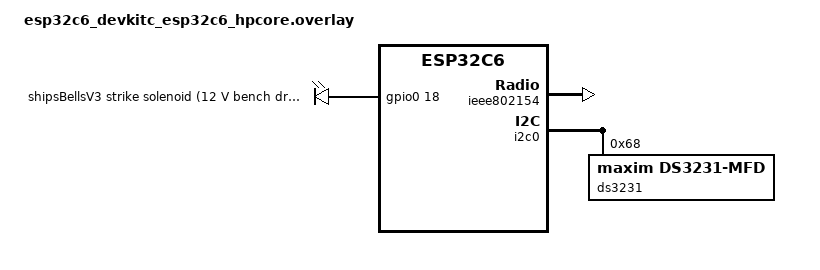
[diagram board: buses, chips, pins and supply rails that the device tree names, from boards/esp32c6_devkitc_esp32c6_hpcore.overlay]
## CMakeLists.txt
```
cmake_minimum_required(VERSION 3.20.0)
find_package(Zephyr REQUIRED HINTS $ENV{ZEPHYR_BASE})
project(tuvm_pulse)

# Task 7 (native_sim bring-up gate): the Model A ("solidified image") boot
# path — vm.c/gc.c/dispatch.c + a per-program src/solidified_image.c baked by
# tools/ns_compile_oevm.py from zephyr/PulseNode.nsl, exactly the recipe
# tools/run_tests_oevm.py uses for the host Path-A test runner (oevm_runner),
# minus src/oevm_main.c (this directory's src/main.c is the Zephyr entry
# point instead). Only src/kernel_boot.c is mutually exclusive with
# solidified_image.c: it defines 13 `Vtable_*` symbols (Vtable_SymbolVtable,
# Vtable_IntegerVtable, ...) that solidified_image.c also bakes for THIS program
# — verified, the overlap is exactly those 13. src/oimg_loader.c does NOT clash
# and is linked under BOTH models: it shares no symbol with solidified_image.c,
# and the host has always linked the two together — tools/run_c_tests.sh:28
# (ENG_A = oimg_loader.c + solidified_image.c) vs :29 (ENG_B = oimg_loader.c +
# kernel_boot.c). The TUVM_MODEL knob below is that same ENG_A/ENG_B split.
# (An earlier revision of this comment blamed oimg_loader.c too, and cited a
# run_c_unit_tests() in tools/run_tests_oevm.py that does not exist — the real
# link sets are in run_c_tests.sh.) src/serial.c and src/udp.c are linked even
# though this gate's node grants no serial/net capability: src/dispatch.c's
# send() fast path unconditionally calls serial_object()/udp_object() to test
# receiver identity, so both — and the zephyr backend files that back them —
# must link regardless (hence prj.conf's native_sim NSOS networking block).
set(TUVM_SRC ${CMAKE_CURRENT_SOURCE_DIR}/..)
target_sources(app PRIVATE
  src/main.c
  ${TUVM_SRC}/src/vm.c ${TUVM_SRC}/src/gc.c ${TUVM_SRC}/src/dispatch.c
  ${TUVM_SRC}/src/platform.c ${TUVM_SRC}/src/space.c ${TUVM_SRC}/src/handles.c
  ${TUVM_SRC}/src/span.c
  ${TUVM_SRC}/src/serial.c ${TUVM_SRC}/src/udp.c ${TUVM_SRC}/src/mirror.c
  ${TUVM_SRC}/src/backend/zephyr/platform_zephyr.c
  ${TUVM_SRC}/src/backend/zephyr/serial_zephyr.c
  ${TUVM_SRC}/src/backend/zephyr/udp_zephyr.c
  ${TUVM_SRC}/src/backend/zephyr/pulse_zephyr.c
  ${TUVM_SRC}/src/backend/zephyr/timer_zephyr.c
  ${TUVM_SRC}/src/backend/zephyr/span_zephyr.c
  ${TUVM_SRC}/src/backend/zephyr/sensor_zephyr.c
  ${TUVM_SRC}/src/http.c
  ${TUVM_SRC}/src/http_core.c
  ${TUVM_SRC}/src/backend/zephyr/http_zephyr.c
)
target_include_directories(app PRIVATE ${TUVM_SRC}/src)

# OpenThread bring-up TU (tuvm_thread_bringup). Gated on OPENTHREAD so the WROOM
# (WiFi, no Thread) compiles it away. ONE shared impl: nRF (NCS) and C6 (upstream
# 4.2) expose the same no-arg OT API, so the earlier board split was redundant
# (#59, 2026-07-20). Re-split behind thread_bringup.h only if the APIs diverge.
if (CONFIG_NET_L2_OPENTHREAD)
  target_sources(app PRIVATE src/thread_bringup.c)
endif()

# ---- Model A/B knob -------------------------------------------------------
# A (default): the per-program baked image, src/solidified_image.c.
# B: a generic VM + a .oimg blob .incbin'd into flash .rodata.
# The link sets are MUTUALLY EXCLUSIVE: solidified_image.c XOR kernel_boot.c —
# see the 13-symbol Vtable_* overlap explained at the top of this file. This is
# the ENG_A/ENG_B split tools/run_c_tests.sh has always used on the host.
#
# Model A links no oimg_loader.c: zephyr/src/main.c stubs the four globals it
# would own (oimg_blob_base/_end, builtin_registry, oimg_singleton), and
# oimg.h's is_in_blob() returns 0 while oimg_blob_base is NULL, so the XIP
# accessor paths are never taken.
set(TUVM_MODEL "B" CACHE STRING "tuvm image model: A (solidified) or B (.oimg blob)")
set_property(CACHE TUVM_MODEL PROPERTY STRINGS A B)

if(TUVM_MODEL STREQUAL "A")
  target_sources(app PRIVATE ${TUVM_SRC}/src/solidified_image.c)
elseif(TUVM_MODEL STREQUAL "B")
  if(NOT DEFINED TUVM_BLOB)
    # Model B is the device default; a bare `west build` (no run.sh, no
    # -DTUVM_BLOB) falls back to the committed TimerNode image so it just works.
    # run.sh bakes a fresh <node>.oimg and passes -DTUVM_BLOB, overriding this.
    set(TUVM_BLOB ${CMAKE_CURRENT_SOURCE_DIR}/TimerNode.oimg)
    message(STATUS "tuvm: TUVM_BLOB defaulted to ${TUVM_BLOB}")
  endif()
  if(NOT EXISTS "${TUVM_BLOB}")
    message(FATAL_ERROR "TUVM_BLOB does not exist: ${TUVM_BLOB}")
  endif()
  target_sources(app PRIVATE
    ${TUVM_SRC}/src/oimg_loader.c
    ${TUVM_SRC}/src/kernel_boot.c
    ${TUVM_SRC}/src/hanoi_native.c
    ${CMAKE_CURRENT_SOURCE_DIR}/blob.S)
  # OEVM_NO_FILE_IO compiles out oimg_loader.c's oimg_load() mmap/open path,
  # which has no meaning on this target.
  target_compile_definitions(app PRIVATE TUVM_MODEL_B OEVM_NO_FILE_IO)
  # blob.S is preprocessed (.S, capital) so TUVM_BLOB_FILE expands.
  set_property(SOURCE ${CMAKE_CURRENT_SOURCE_DIR}/blob.S APPEND PROPERTY
    COMPILE_DEFINITIONS "TUVM_BLOB_FILE=\"${TUVM_BLOB}\"")
  # Rebuild when the blob changes.
  set_property(SOURCE ${CMAKE_CURRENT_SOURCE_DIR}/blob.S APPEND PROPERTY
    OBJECT_DEPENDS "${TUVM_BLOB}")
else()
  message(FATAL_ERROR "TUVM_MODEL must be A or B, got: ${TUVM_MODEL}")
endif()
message(STATUS "tuvm: TUVM_MODEL=${TUVM_MODEL}")

# Tunables via ENV, not `-D`: NCS sysbuild swallows a bare
# `west build -- -DOEVM_HEAP_SIZE=...` (it lands in the sysbuild cache, never
# the app image) — same wrinkle ns-zephyr/app/CMakeLists.txt documents. Env
# vars are inherited by this CMake invocation unconditionally.
if(DEFINED ENV{OEVM_HEAP_SIZE})
  target_compile_definitions(app PRIVATE OEVM_HEAP_SIZE=$ENV{OEVM_HEAP_SIZE})
endif()

# The VM's method/prim inline caches (dispatch.c) default to 4096 entries each
# — 64 KB + 32 KB of static SRAM, host-generous. On the 256 KB nRF52840 that
# dwarfs the arena, so Task 8's DK build shrinks them via env (same env-not-`-D`
# reason as OEVM_HEAP_SIZE above: NCS sysbuild swallows bare `-D` app defines).
# They are pure caches — a smaller table only trades a few more collisions, never
# correctness.
if(DEFINED ENV{METHOD_CACHE_SIZE})
  target_compile_definitions(app PRIVATE METHOD_CACHE_SIZE=$ENV{METHOD_CACHE_SIZE})
endif()
if(DEFINED ENV{PRIM_CACHE_SIZE})
  target_compile_definitions(app PRIVATE PRIM_CACHE_SIZE=$ENV{PRIM_CACHE_SIZE})
endif()

# The boxed-Float arena (gc.c) mallocs slabs of OEVM_FLOAT_ARENA_SLAB_CELLS floats
# (default 4096 ≈ 64 KB/slab — sized for a host's big libc heap). On the DK the
# newlib k_malloc pool is a few tens of KB, so a float-heavy program (e.g.
# perfstex's floatMath) must shrink the slab and bound the slab count via env.
if(DEFINED ENV{OEVM_FLOAT_ARENA_SLAB_CELLS})
  target_compile_definitions(app PRIVATE OEVM_FLOAT_ARENA_SLAB_CELLS=$ENV{OEVM_FLOAT_ARENA_SLAB_CELLS})
endif()
if(DEFINED ENV{OEVM_FLOAT_ARENA_SLAB_BUDGET})
  target_compile_definitions(app PRIVATE OEVM_FLOAT_ARENA_SLAB_BUDGET=$ENV{OEVM_FLOAT_ARENA_SLAB_BUDGET})
endif()

# The VM execution stack (vm.c) is a fixed heap Stack object of VM_STACK_INIT_WORDS
# oops, allocated at boot INSIDE the OEVM_HEAP_SIZE arena — the single largest boot
# allocation (default 16384 words = 64 KB on the 32-bit DK). Shrinking it lowers the
# arena floor, so OEVM_HEAP_SIZE can drop too. OEVM_MARK_STACK_SIZE (gc.c) is the GC
# mark worklist. Both are embedded RAM knobs; passed via env for the same NCS-sysbuild
# reason as the arena/cache defines above.
if(DEFINED ENV{VM_STACK_INIT_WORDS})
  target_compile_definitions(app PRIVATE VM_STACK_INIT_WORDS=$ENV{VM_STACK_INIT_WORDS})
endif()
if(DEFINED ENV{OEVM_MARK_STACK_SIZE})
  target_compile_definitions(app PRIVATE OEVM_MARK_STACK_SIZE=$ENV{OEVM_MARK_STACK_SIZE})
endif()

# Hot-path IRAM placement. Routes the interpreter's hottest functions
# (oevm.h OEVM_HOT) into internal IRAM instead of flash XIP; ends the
# combinator-row cache roulette (ledger E8: ocDo −36%, ~8 KB IRAM).
# Xtensa-only: -mtext-section-literals keeps literal pools in the relocated
# section (an L32R in IRAM cannot reach flash). DEFAULT ON for Xtensa
# (accepted 2026-07-17); export OEVM_IRAM_HOT=0 to opt out. Env, not -D,
# for the same NCS-sysbuild reason as the defines above.
if(CONFIG_XTENSA AND NOT "$ENV{OEVM_IRAM_HOT}" STREQUAL "0")
  target_compile_definitions(app PRIVATE OEVM_HOT_SECTION_IRAM=1)
  target_compile_options(app PRIVATE -mtext-section-literals)
elseif(NOT CONFIG_XTENSA AND "$ENV{OEVM_IRAM_HOT}" STREQUAL "1")
  message(FATAL_ERROR "OEVM_IRAM_HOT is an ESP32/Xtensa knob; unset it for this target")
endif()

# Experiment (2026-07-17): OEOM native-substitution Hanoi spike. OFF by default.
# export OEVM_HANOI_NATIVE=1 to build the native hanoiMove: PrimitiveClosure path
# (src/hanoi_native.c + the strcmp gate in dispatch.c). See
# docs/design/2026-07-17-oeom-native-substitution-hanoi-spike-design.md.
if("$ENV{OEVM_HANOI_NATIVE}" STREQUAL "1")
  target_compile_definitions(app PRIVATE OEVM_HANOI_NATIVE=1)
endif()

# Production default (accepted 2026-07-17): the three per-bytecode debugger
# checks (oevm.h OEVM_NO_DEBUG_HOOKS) are compiled OUT of Zephyr builds —
# no on-target debugger transport exists, and the checks cost 10-16% per
# bytecode (ledger E8). Export OEVM_DEBUG_HOOKS=1 to build a hooks-enabled
# image (required for any future on-target debugging work). Hosted builds
# and the test suites are unaffected — they never define the macro, and the
# debugger-integration gate exercises the hooks there.
if(NOT "$ENV{OEVM_DEBUG_HOOKS}" STREQUAL "1")
  target_compile_definitions(app PRIVATE OEVM_NO_DEBUG_HOOKS=1)
endif()

# Config-D DEFAULTS for every nRF52840 target — LOAD-BEARING, not tuning. The env
# vars above still override, but when the env is silent a 52840 build must NOT fall
# back to the host defaults: without VM_STACK_INIT_WORDS=4096 the VM boots by
# allocating its default 16384-word (64 KB) execution stack inside the 48 KB arena —
# a guaranteed boot OOM. That is precisely how the dongle shipped dead through
# rungs 7-8: built from a shell without the exports, it aborted at boot while
# OpenThread kept it "attached" (see zephyr/docs/BOARD_PORTS.md and
# review/ISSUE-dongle-usb-openthread.md). native_sim/host builds are untouched
# (CONFIG_SOC_NRF52840 is false there, and their 16 MB default arena is fine).
if(CONFIG_SOC_NRF52840)
  if(NOT DEFINED ENV{OEVM_HEAP_SIZE})
    target_compile_definitions(app PRIVATE OEVM_HEAP_SIZE=49152)
  endif()
  if(NOT DEFINED ENV{METHOD_CACHE_SIZE})
    target_compile_definitions(app PRIVATE METHOD_CACHE_SIZE=256)
  endif()
  if(NOT DEFINED ENV{PRIM_CACHE_SIZE})
    target_compile_definitions(app PRIVATE PRIM_CACHE_SIZE=256)
  endif()
  if(NOT DEFINED ENV{VM_STACK_INIT_WORDS})
    target_compile_definitions(app PRIVATE VM_STACK_INIT_WORDS=4096)
  endif()
  if(NOT DEFINED ENV{OEVM_MARK_STACK_SIZE})
    target_compile_definitions(app PRIVATE OEVM_MARK_STACK_SIZE=512)
  endif()
endif()
```

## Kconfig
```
# tuvm app Kconfig — WiFi credentials for the ESP32 HTTP node (#46).
# Values are supplied by the git-ignored overlay prj_esp32_wifi.local.conf;
# the defaults below keep non-WiFi boards (DK/dongle) building.
config TUVM_WIFI_SSID
	string "WiFi SSID for the HTTP node"
	default ""

config TUVM_WIFI_PSK
	string "WiFi WPA2 PSK for the HTTP node"
	default ""

source "Kconfig.zephyr"
```

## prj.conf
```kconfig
# tuvm/zephyr — native_sim bring-up gate (Task 7). Minimal console + a
# generous main stack + heap for the VM arena. No OpenThread (native_sim has
# no radio); no USB-CDC (native_sim's console is the host's own stdout).
CONFIG_CONSOLE=y
CONFIG_STDOUT_CONSOLE=y

# libc with malloc/realloc/free, setjmp, snprintf, FP printf for the VM.
# native_sim selects picolibc by default; NEWLIB_LIBC is a no-op but harmless
# (mirrors ns-zephyr/app/prj_nativesim.conf's own note).
CONFIG_NEWLIB_LIBC=y
CONFIG_NEWLIB_LIBC_FLOAT_PRINTF=y
CONFIG_CBPRINTF_FP_SUPPORT=y
CONFIG_HEAP_MEM_POOL_SIZE=65536

CONFIG_MAIN_STACK_SIZE=16384

# Networking: src/dispatch.c's send() fast path unconditionally probes
# `receiver == udp_object()`, so src/udp.c + src/backend/zephyr/udp_zephyr.c
# must link even though this gate's node never grants a `net` capability.
# native_sim offloaded sockets (NSOS) — verbatim from
# ns-zephyr/app/prj_nativesim.conf, the proven native_sim UDP recipe on this
# workspace. No CONFIG_POSIX_API: it exports a bare `send()` that collides
# with oevm's own `send()` dispatch function in dispatch.c.
CONFIG_NETWORKING=y
CONFIG_NET_IPV6=y
CONFIG_NET_IPV4=y
CONFIG_NET_UDP=y
CONFIG_NET_DRIVERS=y
CONFIG_NET_SOCKETS=y
CONFIG_NET_SOCKETS_OFFLOAD=y
CONFIG_NET_NATIVE_OFFLOADED_SOCKETS=y
CONFIG_ETH_NATIVE_TAP=n
CONFIG_NET_IPV6_DAD=n
CONFIG_NET_MAX_CONTEXTS=8
CONFIG_NET_PKT_RX_COUNT=16
CONFIG_NET_PKT_TX_COUNT=16
CONFIG_NET_BUF_RX_COUNT=32
CONFIG_NET_BUF_TX_COUNT=32
```

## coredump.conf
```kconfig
# Coredump-on-fault overlay for the ESP32. Kept as a recipe, not deleted with the
# crash that motivated it: it is how the fflush fault (EXCCAUSE 28) was localised,
# and it is the tool to reach for the next time a node dies on silicon.
# Applied via -DEXTRA_CONF_FILE=coredump.conf on top of prj_esp32.conf.
# NOT on by default — prj_esp32.conf alone is the normal build.
# The dump is emitted as '#CD:' hex lines over the console using Zephyr's
# low-level logging path (NOT newlib stdio, which the fault gags), so it survives
# the crash. MEMORY_DUMP_MIN = CPU registers (incl. Xtensa EXCCAUSE + the fault
# PC/address) + the faulting thread's stack — enough for a full backtrace and to
# see the bad pointer, while keeping the serial dump short. Decode offline with
# zephyr/scripts/coredump/.
CONFIG_DEBUG_COREDUMP=y
CONFIG_DEBUG_COREDUMP_BACKEND_LOGGING=y
CONFIG_DEBUG_COREDUMP_MEMORY_DUMP_MIN=y
```

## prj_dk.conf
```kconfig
# tuvm/zephyr — Task 8 (nRF52840-DK acceptance bar) Kconfig.
#
# Selected explicitly with `west build -b nrf52840dk/nrf52840 -- -DCONF_FILE=prj_dk.conf`
# so the native_sim gate's prj.conf (Task 7) is NOT consulted — its NSOS
# offloaded-sockets block is native_sim-only and has no meaning on silicon. This
# file is the on-target counterpart: the SAME engine + zephyr backend, but with
# the console on the DK's uart0/VCOM and Zephyr's REAL in-kernel UDP stack over a
# loopback interface (the proven nRF52840 recipe from
# ns-zephyr/app/prj_dongle_loopback.conf).

# Console on uart0 -> the DK's on-board SEGGER VCOM (/dev/ttyACM0 on the host).
# This is the DK board default; stated explicitly for provenance. No USB-CDC:
# the DK routes its console to uart0, unlike the dongle.
CONFIG_CONSOLE=y
CONFIG_UART_CONSOLE=y
CONFIG_STDOUT_CONSOLE=y

# libc with malloc/realloc/free, setjmp, snprintf, FP printf for the VM arena.
# Sizes trimmed for the nRF52840's 256 KB SRAM (the native_sim gate's 64 KB pool
# / 16 KB stack are host-generous): the VM's own arena is the static
# `oevm_heap_store` (gc.c), sized by the OEVM_HEAP_SIZE compile-def passed via
# env at build time (65536 here — ~72 KB incl. the 1-bit-per-granule GC bitmap),
# NOT by CONFIG_HEAP_MEM_POOL_SIZE (that is Zephyr's own k_malloc pool, used by
# the net stack). 16 KB pool + 8 KB main stack mirror ns-zephyr's proven
# nRF52840 loopback config.
CONFIG_NEWLIB_LIBC=y
CONFIG_NEWLIB_LIBC_FLOAT_PRINTF=y
CONFIG_CBPRINTF_FP_SUPPORT=y
CONFIG_HEAP_MEM_POOL_SIZE=16384
CONFIG_MAIN_STACK_SIZE=8192
CONFIG_FPU=y

# GPIO: the on-board BUTTON1 (P0.11) is the physical edge source. The board DTS
# already enables gpio0; the overlay adds the `pulsegpio` alias onto button0.
CONFIG_GPIO=y

# Networking: Zephyr's in-kernel IPv6 + IPv4 UDP over a loopback interface —
# same reason as the native_sim gate, src/dispatch.c's send() fast path
# unconditionally probes `receiver == udp_object()`, so src/udp.c +
# src/backend/zephyr/udp_zephyr.c must LINK even though this gate's node grants
# no `net` capability. On silicon that means the real stack (no NSOS). NO
# CONFIG_POSIX_API: it exports a bare send() that collides with oevm's own
# send() dispatch function. Verbatim from ns-zephyr/app/prj_dongle_loopback.conf.
CONFIG_NETWORKING=y
CONFIG_NET_IPV6=y
CONFIG_NET_IPV4=y
CONFIG_NET_UDP=y
CONFIG_NET_SOCKETS=y
CONFIG_NET_DRIVERS=y
CONFIG_NET_LOOPBACK=y
CONFIG_NET_CONFIG_SETTINGS=y
CONFIG_NET_CONFIG_NEED_IPV6=y
CONFIG_NET_CONFIG_MY_IPV6_ADDR="::1"
CONFIG_NET_CONFIG_NEED_IPV4=y
CONFIG_NET_CONFIG_MY_IPV4_ADDR="127.0.0.1"
# Buffer counts trimmed vs the dongle recipe: this gate NEVER moves a packet
# (the net stack is present only so udp_zephyr.c's zsock_* references link), so
# the minimum that boots the loopback interface is enough — saves SRAM for the
# VM arena on the 256 KB part.
CONFIG_NET_MAX_CONTEXTS=4
CONFIG_NET_PKT_RX_COUNT=4
CONFIG_NET_PKT_TX_COUNT=4
CONFIG_NET_BUF_RX_COUNT=8
CONFIG_NET_BUF_TX_COUNT=8
```

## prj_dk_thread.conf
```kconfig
# tuvm/zephyr/prj_dk_thread.conf — Rung 7 (Layer 3): NetBridge over real
# OpenThread on the nRF52840-DK, MTD child. Selected with
# `-DCONF_FILE=prj_dk_thread.conf`; the gitignored prj_dk_thread_local.conf is
# layered via `-DEXTRA_CONF_FILE` and overrides the placeholder dataset below.
#
# Console on uart0 -> on-board SEGGER VCOM (/dev/ttyACM0). No USB-CDC: the DK
# routes its console to uart0, so the ns-zephyr USB-coexistence config
# (USBD_CDC_ACM_WORKQUEUE, deferred enable, MANUAL_START) is NOT needed here.
CONFIG_CONSOLE=y
CONFIG_UART_CONSOLE=y
CONFIG_STDOUT_CONSOLE=y

# libc with malloc/realloc/free, setjmp, snprintf, FP printf for the VM arena.
CONFIG_NEWLIB_LIBC=y
CONFIG_NEWLIB_LIBC_FLOAT_PRINTF=y
CONFIG_CBPRINTF_FP_SUPPORT=y
CONFIG_FPU=y
# System heap: OT + mbedTLS + net boot-time allocs draw on this pool (NOT the VM
# arena, which is the static oevm_heap_store sized by OEVM_HEAP_SIZE). ns-zephyr
# learned 16384 is too small for the OT boot path; use 32768.
CONFIG_HEAP_MEM_POOL_SIZE=32768
CONFIG_MAIN_STACK_SIZE=8192

# GPIO: the on-board BUTTON1 (P0.11) is the physical send trigger (Task-8 seam).
CONFIG_GPIO=y

# --- Networking: IPv6 UDP over OpenThread (IEEE 802.15.4 mesh), MTD child ------
CONFIG_NETWORKING=y
CONFIG_NET_IPV6=y
CONFIG_NET_UDP=y
CONFIG_NET_SOCKETS=y
CONFIG_NET_L2_OPENTHREAD=y
# MTD, never FTD (David, firm — FTD's MPSL/radio/RAM weight faulted at boot and
# sat at 91% RAM). A leaf attaches as a child of the OTBR and sends through it.
CONFIG_OPENTHREAD_MTD=y
CONFIG_OPENTHREAD_FTD=n
# MANUAL_START: the app owns OT bring-up (src/main.c thread_bringup()), mirroring
# ns-zephyr's main_b.c. Rung-7 lesson: with auto-start the boot SYS_INIT calls
# openthread_run() (enables IPv6+Thread, node attaches) but NEVER net_if_up() on
# the Zephyr OT iface, and with NET_CONFIG off nothing else does either — so
# zsock_sendto fails ENETDOWN even though OT is attached (ping works, sockets
# don't). main.c calls openthread_run() + net_if_up() explicitly after boot.
CONFIG_OPENTHREAD_MANUAL_START=y
# OT init runs PSA/AES-CCM link crypto on this stack at boot; too small -> MPU
# fault before the console comes up (ns-zephyr lesson). 6240 is the proven size.
CONFIG_OPENTHREAD_THREAD_STACK_SIZE=6240
# NET_CONFIG OFF: its SYS_INIT blocks boot waiting for an IPv6 address and
# deadlocks a Thread node (ns-zephyr lesson). The node binds its own sockets.
CONFIG_NET_CONFIG_SETTINGS=n
CONFIG_NET_MAX_CONTEXTS=6
CONFIG_NET_PKT_RX_COUNT=8
CONFIG_NET_PKT_TX_COUNT=8
CONFIG_NET_BUF_RX_COUNT=16
CONFIG_NET_BUF_TX_COUNT=16

# --- Thread dataset persistence + the flash-erase lesson -----------------------
# OT persists its active dataset to NVS. A blocking flash erase at boot must be
# time-sliced (PARTIAL_ERASE) so it does not stall the system for long stretches
# (ns-zephyr's hard-won line; kept even though the DK has no USB to starve).
CONFIG_FLASH=y
CONFIG_FLASH_MAP=y
CONFIG_NVS=y
CONFIG_SETTINGS=y
CONFIG_SETTINGS_NVS=y
CONFIG_SOC_FLASH_NRF_PARTIAL_ERASE=y
CONFIG_SOC_FLASH_NRF_PARTIAL_ERASE_MS=2
CONFIG_SYSTEM_WORKQUEUE_STACK_SIZE=2048

# --- Thread dataset SEED — PLACEHOLDER (OpenThread defaults) --------------------
# SECRET: the REAL porta dataset (incl. network key) lives ONLY in the gitignored
# prj_dk_thread_local.conf, layered via -DEXTRA_CONF_FILE, overriding these. The
# node builds without the overlay but will NOT join the porta mesh.
CONFIG_OPENTHREAD_NETWORKKEY="00:11:22:33:44:55:66:77:88:99:aa:bb:cc:dd:ee:ff"
CONFIG_OPENTHREAD_PANID=43981
CONFIG_OPENTHREAD_CHANNEL=11
CONFIG_OPENTHREAD_XPANID="de:ad:00:be:ef:00:ca:fe"
CONFIG_OPENTHREAD_NETWORK_NAME="ot_zephyr"
```

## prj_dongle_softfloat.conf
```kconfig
# Fallback experiment for review/ISSUE-dongle-usb-openthread.md next-step 2:
# the ONLY structural .config delta left vs st-zephyr's WORKING dongle image
# (test-dongle-06-jast-ftd) after the pm_static_dongle.yml fix is the float ABI —
# ours hard-float, theirs soft-float — which selects a DIFFERENT prebuilt MPSL
# (radio arbiter) library (MPSL_LIB_FLOAT_ABI_DIR hard-float vs soft-float).
# This fragment flips ours to match. Stack this AFTER the local conf:
#   -DEXTRA_CONF_FILE="prj_dongle_thread_local.conf;prj_dongle_softfloat.conf"
# Flash ONLY if the pm_static-fixed hard-float image still fails to enumerate.
CONFIG_FPU=n
```

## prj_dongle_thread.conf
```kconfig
# tuvm/zephyr/prj_dongle_thread.conf — Rung 7 (Layer 3), nRF52840 DONGLE port.
# Same NetBridge-over-OpenThread MTD node as the DK, but for the PCA10059 dongle:
# console on the SoC USB-CDC (the dongle has no debugger/VCOM), and picolibc.
# Selected with `-DCONF_FILE=prj_dongle_thread.conf`; the gitignored
# prj_dongle_thread_local.conf overrides the placeholder dataset via -DEXTRA_CONF_FILE.
# See docs/BOARD_PORTS.md + docs/ZEPHYR_LESSONS.md for the why behind every line.
#
# --- Console: SoC USB-CDC ACM (the dongle has no uart0/VCOM) --------------------
#
# "ISSUE A" IS SOLVED, AND IT WAS ONE MISSING KCONFIG LINE (2026-07-11).
#
# It was recorded for two rungs as "the USB-CDC console dies under the radio", with
# picolibc-vs-newlib as the leading suspect. Both were WRONG. The truth:
#
#   CONFIG_USB_DEVICE_STACK_NEXT is Zephyr's NEW USB device stack, and under it the
#   USB device is NOT brought up automatically — something must initialize + enable
#   it. Rung 7 set USB_DEVICE_STACK_NEXT=y + USBD_CDC_ACM_CLASS=y but never set
#   CONFIG_CDC_ACM_SERIAL_INITIALIZE_AT_BOOT=y, and src/main.c never called
#   usbd_enable(). So NOTHING ever started USB. It had nothing to do with the radio:
#   the console never enumerated, at any time, under any conditions.
#
# This block is Zephyr's own supported recipe — see zephyr/snippets/cdc-acm-console
# (equivalently: build with `-S cdc-acm-console`). The one load-bearing line is
# CDC_ACM_SERIAL_INITIALIZE_AT_BOOT.
#
# CAUTION — UART_LINE_CTRL=y makes the FIRST console write BLOCK until a host opens
# the port and asserts DTR. That is fine when a host is attached (read with pyserial
# dtr=True, NOT `cat`), but it means an UNATTENDED dongle can block on its first
# print. platform_console_write() must therefore never be able to wedge the VM on a
# board whose console has no reader — see src/backend/zephyr/platform_zephyr.c.
CONFIG_USB_DEVICE_STACK_NEXT=y
CONFIG_USBD_CDC_ACM_CLASS=y
CONFIG_USBD_CDC_ACM_WORKQUEUE=y
CONFIG_CDC_ACM_SERIAL_INITIALIZE_AT_BOOT=y   # bug 1: nothing ever started USB
CONFIG_SERIAL=y
CONFIG_CONSOLE=y
CONFIG_UART_CONSOLE=y
CONFIG_UART_LINE_CTRL=y
CONFIG_STDOUT_CONSOLE=y
CONFIG_CBPRINTF_COMPLETE=y

# A fatal error must leave EVIDENCE on the console, not silently reboot into a
# fresh boot that looks like a healthy one (which is how the dongle hid for 2 rungs).
CONFIG_RESET_ON_FATAL_ERROR=n

# libc: picolibc (jast's default; -~12KB flash vs newlib, zero functional cost;
# the leading fix for the dongle Issue A). FP printf still required (VM prints %g).
CONFIG_PICOLIBC=y
CONFIG_PICOLIBC_IO_FLOAT=y
CONFIG_CBPRINTF_FP_SUPPORT=y
CONFIG_FPU=y
# System heap: OT + mbedTLS + net boot-time allocs draw on this pool (NOT the VM
# arena, sized by OEVM_HEAP_SIZE). 16384 is too small for the OT boot path; 32768.
CONFIG_HEAP_MEM_POOL_SIZE=32768
CONFIG_MAIN_STACK_SIZE=8192

# GPIO: the dongle's SW1 (P1.06, board button0) is the physical send trigger,
# exposed as the `pulsegpio` alias in boards/nrf52840dongle_nrf52840.overlay.
CONFIG_GPIO=y

# --- Networking: IPv6 UDP over OpenThread (IEEE 802.15.4 mesh), MTD child ------
CONFIG_NETWORKING=y
CONFIG_NET_IPV6=y
CONFIG_NET_UDP=y
CONFIG_NET_SOCKETS=y
CONFIG_NET_L2_OPENTHREAD=y
# MTD, never FTD (FTD's MPSL/radio/RAM weight faulted at boot on the dongle).
CONFIG_OPENTHREAD_MTD=y
CONFIG_OPENTHREAD_FTD=n
# MANUAL_START: the app owns OT bring-up (src/main.c thread_bringup()). On the
# dongle this is doubly important — auto-start's openthread_run() on the BOOT path
# starves USB enumeration. thread_bringup() runs it AFTER the 3s USB settle, then
# calls net_if_up() (the rung-7 ENETDOWN fix).
CONFIG_OPENTHREAD_MANUAL_START=y

# *** THE LINE THAT MAKES A USB-CDC CONSOLE AND A RADIO COEXIST (bug 2). ***
#
# MANUAL_START alone is NOT enough: it only defers openthread_run(). OpenThread's
# SYS_INIT still runs at BOOT, before main() — bringing up the 802.15.4 radio and its
# clocks — and THAT is what stops the SoC USB from ever enumerating. Proven by bisect
# (2026-07-11): stock hello_world + the cdc-acm-console snippet enumerates fine; add
# ONLY this OpenThread block and USB goes dead. Nothing else of ours is involved.
#
# SYS_INIT=n defers OT init entirely to the application, which is the architecture
# src/main.c already implements and could never benefit from: its 3s USB settle was
# pointless while OT had already initialized before main() ran. With this line the boot
# order finally becomes: USB init -> main() -> 3s settle (USB ENUMERATES) ->
# thread_bringup() (openthread_init + openthread_run + net_if_up) -> attach.
#
# thread_bringup() already calls openthread_init(), so it is correct with SYS_INIT off.
# Recovered from st-zephyr's working dongle config (tests/dongle/test-dongle-06-jast-ftd)
# — this is the "jast" technique, and it was the real content of "Issue A" all along.
CONFIG_OPENTHREAD_SYS_INIT=n
CONFIG_MBEDTLS_HEAP_SIZE=10240
# OT init runs PSA/AES-CCM link crypto on this stack; <~3168 -> MPU fault (silent
# boot). 6240 is the proven size.
CONFIG_OPENTHREAD_THREAD_STACK_SIZE=6240
# NET_CONFIG OFF: its SYS_INIT blocks boot up to 30s waiting for an IPv6 address
# and deadlocks a Thread node (silent boot). The node binds its own sockets.
CONFIG_NET_CONFIG_SETTINGS=n
CONFIG_NET_MAX_CONTEXTS=6
CONFIG_NET_PKT_RX_COUNT=8
CONFIG_NET_PKT_TX_COUNT=8
CONFIG_NET_BUF_RX_COUNT=16
CONFIG_NET_BUF_TX_COUNT=16

# --- Thread dataset persistence + the flash-erase lesson -----------------------
# On the dongle the PARTIAL_ERASE lines are CRITICAL (not just tidy): a blocking
# flash erase at boot drops USB CDC IRQs -> CDC never enumerates -> silent boot.
CONFIG_FLASH=y
CONFIG_FLASH_MAP=y
CONFIG_NVS=y
CONFIG_SETTINGS=y
CONFIG_SETTINGS_NVS=y
CONFIG_SOC_FLASH_NRF_PARTIAL_ERASE=y
CONFIG_SOC_FLASH_NRF_PARTIAL_ERASE_MS=2
CONFIG_SYSTEM_WORKQUEUE_STACK_SIZE=2048

# --- Thread dataset SEED — PLACEHOLDER (OpenThread defaults) --------------------
# SECRET: the REAL porta dataset lives ONLY in the gitignored
# prj_dongle_thread_local.conf, layered via -DEXTRA_CONF_FILE, overriding these.
CONFIG_OPENTHREAD_NETWORKKEY="00:11:22:33:44:55:66:77:88:99:aa:bb:cc:dd:ee:ff"
CONFIG_OPENTHREAD_PANID=43981
CONFIG_OPENTHREAD_CHANNEL=11
CONFIG_OPENTHREAD_XPANID="de:ad:00:be:ef:00:ca:fe"
CONFIG_OPENTHREAD_NETWORK_NAME="ot_zephyr"
```

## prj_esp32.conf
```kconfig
# tuvm/zephyr — ESP32 (ESP32-D0WDQ6 / WROOM-32) boot-&-run Kconfig.
#
# Selected with:
#   west build -b esp32_devkitc/esp32/procpu -- -DCONF_FILE=prj_esp32.conf
# built against the upstream-Zephyr workspace ~/zephyr-esp32 (NOT NCS — ESP32 is
# first-class upstream, absent from NCS's manifest). This is the on-silicon
# counterpart to prj_dk.conf: the SAME engine + zephyr backend, console on
# uart0 (the CP210x USB-serial bridge, /dev/ttyUSB0 on the host), and Zephyr's
# REAL in-kernel UDP stack over a loopback interface.
#
# First target node is TimerNode (Rung-8 gate 1): it exercises the REAL
# k_timer ISR path (timer_zephyr.c) and needs NO radio and NO GPIO, so this
# config omits the DK's GPIO block. main.c's GPIO ISR is guarded on
# DT_ALIAS(pulsegpio) — absent here (no board overlay) — so it compiles out;
# OpenThread is guarded on CONFIG_NET_L2_OPENTHREAD (off here).

# Console on uart0 -> the devkit's CP210x USB-serial (/dev/ttyUSB0 on the host).
# esp32_devkitc's board DTS already chooses uart0 as zephyr,console; stated
# explicitly for provenance. Not USB-CDC (classic ESP32 has no native USB), so
# main.c's cdc_acm console branch compiles out.
# The bench board is an ESP32-D0WDQ6 rev v1.0 (early-2016 silicon). The
# hal_espressif SoC bootloader HALTS on rev 1.0 unless this opt-in is set —
# without it the app never gets control (bootloader stops at soc_init). Harmless
# on newer revisions.
CONFIG_ESP32_USE_UNSUPPORTED_REVISION=y

CONFIG_CONSOLE=y
CONFIG_SERIAL=y
CONFIG_UART_CONSOLE=y
CONFIG_STDOUT_CONSOLE=y

# libc: picolibc (Zephyr's DEFAULT libc — lib/libc/Kconfig defaults PICOLIBC
# unless a target REQUIRES_FULL_LIBC). We deliberately do NOT reuse the nRF DK's
# CONFIG_NEWLIB_LIBC here. NOTE: an earlier revision of this comment blamed the
# 'TIMER OK' crash on newlib lazily mallocing the stream buffer, and claimed
# picolibc "doesn't have this gap". That was WRONG — picolibc crashed
# identically, because the choice of libc never mattered: the ESP32 ROM linker
# script esp32.rom.newlib-funcs.ld assigns `fflush` as a STRONG symbol (plain
# assignment, not PROVIDE — see that file's header comment, which says this is
# deliberate "so that ROM functions are always used instead of the ones provided
# by libc.a"). So fflush bound to ROM newlib no matter what, and ROM fflush
# calls ROM __getreent, which reads an ESP-IDF/FreeRTOS TCB reent pointer that
# does not exist under Zephyr -> NULL load -> EXCCAUSE 28. Verified by nm on
# zephyr.elf: `fflush` is absolute at 0x40059394 (ROM) while printf/fwrite/fputc
# resolve to picolibc at 0x400f____ — fflush was the ONLY stdio call tuvm made
# that appears on that forced list, which is why the text printed and then the
# flush faulted. Fixed at the source: platform_console_flush() is a no-op on
# Zephyr (stdout is _IONBF, so nothing is buffered) — see
# src/backend/zephyr/platform_zephyr.c. picolibc remains the right choice: the
# VM needs malloc/realloc/free, setjmp, snprintf and FP
# printf — all provided by picolibc (CONFIG_PICOLIBC_IO_FLOAT for %g/%f). The
# VM's own arena is the static oevm_heap_store (gc.c), sized by OEVM_HEAP_SIZE at
# build time; RAM tuning reuses the DK's proven env exports. ESP32 has an FPU.
CONFIG_PICOLIBC=y
CONFIG_PICOLIBC_IO_FLOAT=y
CONFIG_CBPRINTF_FP_SUPPORT=y
CONFIG_HEAP_MEM_POOL_SIZE=16384
CONFIG_MAIN_STACK_SIZE=8192
CONFIG_FPU=y

# Networking: WiFi (2.4 GHz WROOM-32 radio) + TCP/IPv4 + DHCPv4 for the HTTP node.
# src/dispatch.c's send() fast path unconditionally probes
# `receiver == udp_object()`, so src/udp.c + src/backend/zephyr/udp_zephyr.c
# must LINK regardless; that path now rides the same WiFi interface as HTTP
# instead of loopback (#46 — see zephyr/src/backend/zephyr/http_zephyr.c and
# main.c's wifi_bringup()). NO CONFIG_POSIX_API: it exports a bare send() that
# collides with oevm's own send() dispatch function in dispatch.c.
CONFIG_NETWORKING=y
CONFIG_NET_IPV4=y
CONFIG_NET_TCP=y
CONFIG_NET_UDP=y
CONFIG_NET_SOCKETS=y
CONFIG_NET_DHCPV4=y

# WiFi driver + the wifi_mgmt / net_mgmt request API used by wifi_bringup().
CONFIG_WIFI=y
CONFIG_WIFI_ESP32=y
CONFIG_NET_L2_WIFI_MGMT=y
CONFIG_NET_MGMT=y
CONFIG_NET_MGMT_EVENT=y
CONFIG_NET_L2_ETHERNET=y

# Net-buffer / context counts for a small TCP server. Starting point; trim or
# raise at bring-up if RAM is tight or connections stall (see the design risk).
# TRIMMED (2026-07-18, this task): the brief's starting values (8/8/8/16/16)
# overflowed DRAM by 4776 B once WiFi's own CONFIG_HEAP_MEM_POOL_ADD_SIZE_ESP_WIFI
# (+40960 B system heap for the driver, ESP_WIFI_HEAP_SYSTEM default) is added on
# top of OEVM_HEAP_SIZE. Halved back to the values the pre-WiFi loopback config
# already proved boot clean at this same OEVM_HEAP_SIZE (run.sh's 65536) —
# net_buf pools (CONFIG_NET_BUF_DATA_SIZE=128) dominate the 4776 B, so RX/TX
# 16->8 alone recovers ~2.4 KB; PKT/context halving covers the rest.
# NET_MAX_CONTEXTS=5: 1 always-open listen socket (http_listen(), held for the
# VM's whole lifetime — see src/backend/zephyr/http_zephyr.c) + 4 in-flight
# accepted connections (OEVM_HTTP_INFLIGHT=4, src/http_backend.h). At =4 the
# listen socket alone left only ~3 contexts for accepted connections, and a
# context-exhausted zsock_accept() in http_poll() is indistinguishable from
# "nothing pending" (both take the same early return) — so a client would be
# silently dropped instead of hitting the ring's graceful 503 shed.
CONFIG_NET_MAX_CONTEXTS=5
# TIME_WAIT 1500 -> 250 ms (#65). Those 4 connection contexts are not freed at
# close: every reply is HTTP/1.0 + `Connection: close`, so the NODE is the active
# closer and parks each context in TIME_WAIT for the full delay. 4 contexts held
# 1500 ms each is a hard sustained ceiling of 4/1.5s = 2.67 requests/second, and
# every request above it is RST by the TCP stack BELOW zsock_accept() — so the
# ring's graceful 503 shed never sees it (that shed only fires for a connection
# already accepted; under connection-rate overload it is unreachable by
# construction). Measured on the WROOM-32 before the change, and this is the
# whole of the issue's rate table rather than two regimes: a quiesced node
# accepted exactly 4 back-to-back, refused everything for the next 1513 ms, then
# resumed — 1513 ms being TIME_WAIT to within the 150 ms probe granularity.
# Achieved throughput was pinned at 2.44-2.82/s at every offered rate from 4/s to
# unpaced, with ZERO failures below it.
# 250 ms restores 4/0.25s = ~16/s. The trade is TIME_WAIT's own purpose — guarding
# against delayed segments from a previous connection reusing the same 4-tuple —
# and Zephyr's Kconfig help sanctions exactly this trade for exactly this reason:
# "For low-resource systems, having large MSL may lead to quick resource
# exhaustion (and related DoS attacks)", noting the misdelivery risk "is largely
# alleviated in the modern TCP stacks by using random, non-repeating port numbers
# and initial sequence numbers". Zephyr's 1500 is already far below the RFC 793
# 2*MSL of 2 minutes for the same reason; this goes one step further on a LAN.
# Costs no RAM, which is why it is the first lever and not more contexts (#53:
# dram0 has 816 B spare). The protocol-level fix is keep-alive, which removes the
# per-request connection entirely — see #65.
CONFIG_NET_TCP_TIME_WAIT_DELAY=250
# TCP keep-alive (#65) — the reaper for idle ESTABLISHED connections, and the one
# change that BREAKS the fatal deadlock rather than making it less likely.
# Measured on target: four un-accepted backlog connections sat in ESTABLISHED with
# the RX packet slab at 0/8, permanently. Without this symbol an idle ESTABLISHED
# connection has NO timer of any kind — not a slow timeout, none — so nothing was
# ever going to reclaim them and the node stayed deaf until a hardware reset.
# The per-connection timings are set in http_listen() rather than by the Kconfig
# defaults, which are useless here (idle 7200 s); see that comment for why the
# option must go on the LISTENING socket to reach a backlog entry at all.
CONFIG_NET_TCP_KEEPALIVE=y
# TX pool provisioned to serve a multi-KB body (the ~4 KB /thermal SVG): at the
# original 4 pkt / 8 buf the ESP32 TCP stack RST the connection mid-body (send
# returned ENOTCONN=128 after the first 512 B chunk). Funded by reverting the
# MAIN_STACK_SIZE bump (the crash was ROM setjmp, not stack). NET_BUF_DATA_SIZE 256
# so fewer bufs cover a full TCP window.
# RX descriptors 8 -> 16 (#65), restoring the value #46's RAM trim halved. This is
# the "raise the bar" lever, and it is deliberately taken IN ADDITION to the
# keep-alive reaper, not instead of it: more descriptors make the starvation
# window harder to reach, but only the reaper can end it once reached. Measured
# root cause was this slab hitting 0/8 with four backlogged connections pinning it,
# so the pool that the wedge exhausts is the one worth widening. Funded by the
# dram0 headroom the arena reduction freed (#53).
CONFIG_NET_PKT_RX_COUNT=16
CONFIG_NET_PKT_TX_COUNT=16
CONFIG_NET_BUF_RX_COUNT=16
CONFIG_NET_BUF_TX_COUNT=32
CONFIG_NET_BUF_DATA_SIZE=256
CONFIG_NET_TCP_MAX_SEND_WINDOW_SIZE=4096
CONFIG_NET_CONFIG_SETTINGS=n

# AMG8833 Grid-EYE thermal array (AMG88XX selects I2C). Phase 1 is poll-only: the
# cadence lives in nsl (ThermalNode's timer), so no driver trigger thread is needed
# and TRIGGER_NONE keeps the footprint down. Task 9 switches this to a trigger mode
# when the threshold event lands.
CONFIG_SENSOR=y
CONFIG_AMG88XX=y
CONFIG_AMG88XX_TRIGGER_NONE=y
```

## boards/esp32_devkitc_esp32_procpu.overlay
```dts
/* AMG8833 Grid-EYE on the WROOM-32's i2c0.
 *
 * FILENAME IS LOAD-BEARING. Zephyr auto-applies boards/<board>_<qualifiers>.overlay,
 * where the qualifiers of the board target `esp32_devkitc/esp32/procpu` are joined
 * with underscores (cmake/modules/extensions.cmake:1709-1712) — hence
 * `esp32_devkitc_esp32_procpu.overlay`. A plain `esp32_devkitc.overlay` is NOT a name
 * the build looks for: it would be silently ignored, the amg88xx node would never
 * exist, DT_NODE_EXISTS would compile the backend's #else branch, and every frame
 * would read nil with no error anywhere. If the sensor never appears, check first
 * that the build log says "Found devicetree overlay: .../boards/<this file>".
 *
 * Pins verified against the board devicetree
 * (~/zephyr-esp32/zephyr/boards/espressif/esp32_devkitc/esp32_devkitc_procpu.dts:83-90):
 *   SDA -> GPIO21, SCL -> GPIO22, and i2c0 is already status = "okay" with
 *   clock-frequency set there, so this overlay only adds the sensor node.
 *
 * Wiring: VIN -> 3V3, GND -> GND, SDA -> GPIO21, SCL -> GPIO22, INT -> GPIO4.
 *
 * `int-gpios` is REQUIRED by the panasonic,amg88xx binding even in the no-trigger
 * phase-1 build (CONFIG_AMG88XX_TRIGGER_NONE=y), so the INT pin must be physically
 * wired or the driver will not initialize. It is open-drain active-low, so it needs a
 * pull-up; most breakouts have one on INT, and GPIO_PULL_UP is set here so the build
 * does not depend on that. GPIO4 was checked free — nothing in the board devicetree
 * claims it.
 *
 * Default I2C address is 0x69; it is 0x68 when AD_SELECT is tied low. If the device
 * does not probe, scan the bus before suspecting the driver — a strapped-low board
 * needs both the node name and `reg` changed to 0x68.
 */
#include <zephyr/dt-bindings/gpio/gpio.h>

&i2c0 {
	status = "okay";

	amg88xx: amg88xx@69 {
		compatible = "panasonic,amg88xx";
		reg = <0x69>;
		int-gpios = <&gpio0 4 (GPIO_ACTIVE_LOW | GPIO_PULL_UP)>;
		status = "okay";
	};
};
```

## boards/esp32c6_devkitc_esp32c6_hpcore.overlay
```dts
/* Enable the C6's built-in 802.15.4 radio for OpenThread.
 *
 * esp32c6_common.dtsi:85 declares:
 *     ieee802154: ieee802154 { compatible = "espressif,esp32-ieee802154";
 *                              status = "disabled"; };
 * CONFIG_IEEE802154_ESP32 depends on DT_HAS_ESPRESSIF_ESP32_IEEE802154_ENABLED,
 * so the driver does not build until this node is enabled.
 *
 * Filename is derived from the board qualifiers (esp32c6_devkitc/esp32c6/hpcore
 * -> esp32c6_devkitc_esp32c6_hpcore.overlay). CMake CACHES overlay discovery, so
 * a newly-added overlay needs -p always on the first build after adding it.
 */
#include <zephyr/dt-bindings/gpio/gpio.h>   /* GPIO_ACTIVE_LOW / GPIO_PULL_UP below */

&ieee802154 {
	status = "okay";
};

/* tuvm#100 — DS3231 on the C6's i2c0, the shipsBellsV3 timebase.
 *
 * i2c0 is ALREADY status = "okay" with clock-frequency = I2C_BITRATE_FAST in the
 * board devicetree (esp32c6_devkitc_hpcore.dts:53-58) on SDA -> GPIO6, SCL ->
 * GPIO7 (esp32c6_devkitc_hpcore-pinctrl.dtsi:38-39), so this overlay adds only
 * the device nodes. Same shape as the WROOM-32's amg88xx overlay next door,
 * including the load-bearing filename rule stated in that file's header.
 *
 * TWO NODES, not one: Zephyr's DS3231 support is an MFD. The parent
 * `maxim,ds3231-mfd` owns the I2C address and the shared register access; the
 * `maxim,ds3231-rtc` CHILD is what CONFIG_RTC_DS3231 binds and what
 * DEVICE_DT_GET must name. Pointing the alias at the parent yields a device with
 * no RTC API and rtc_get_time() fails at runtime with no build error.
 *
 * WIRING (bench, 2026-07-31): module VCC -> 3V3, GND -> GND, SDA -> GPIO6,
 * SCL -> GPIO7, SQW -> GPIO10. Power the module from 3V3 and NOT 5V: its
 * on-board R22/R23 pull SDA/SCL up to whatever VCC is fed, straight onto the
 * C6's pins. Do not add pull-ups here — the module already carries 10k on SDA,
 * SCL and INT/SQW (R21/R22/R23), so GPIO_PULL_UP below is belt-and-braces for a
 * module that lacks them, not a second parallel resistor worth worrying about.
 *
 * `isw-gpios` IS MANDATORY, and not because the binding says so — the binding
 * leaves it optional. The driver's device macro reads it with
 * GPIO_DT_SPEC_INST_GET, not the _OR form it uses for freq-32khz-gpios
 * (drivers/rtc/rtc_ds3231.c:855), so omitting the property is a COMPILE error,
 * not a graceful degradation. It is declared here ahead of the wire existing.
 * Nothing touches the pin while CONFIG_RTC_ALARM and CONFIG_RTC_UPDATE are both
 * off: rtc_ds3231_init_isw() — the only code that configures it — is inside
 * `#if defined(CONFIG_RTC_UPDATE) || defined(CONFIG_RTC_ALARM)` and both default
 * to n. Turning either on before the wire is physically in place makes device
 * init return -ENODEV and the whole RTC disappears, which is worth knowing
 * because it presents as "the driver is broken" rather than "the pin is
 * floating".
 *
 * GPIO10 was checked free on this part: nothing in the board devicetree claims
 * it, it is not a strapping pin (4/5/8/9/15), not USB (12/13), not the UART0
 * console (16/17), and not SPI flash (24-29 — ngpios is 30).
 *
 * freq-32khz-gpios is deliberately ABSENT. That pin is not wired, and the
 * driver does not use it either way (the binding says so outright); the seam
 * reads the time over I2C rather than disciplining anything against a 32 kHz
 * edge, which is exactly what the shipsBellsV3 design deleted along with the
 * MagTag's integrator (tuvm#101).
 *
 * The part on the bench module is marked DS3231M (MEMS, +/-5 ppm), not the
 * +/-2 ppm TCXO the run-of-five specifies. Same driver, same registers, worse
 * drift — see docs/design/2026-07-26-shipsbellsv3-design.md §95.
 */
&i2c0 {
	status = "okay";

	ds3231: ds3231@68 {
		compatible = "maxim,ds3231-mfd";
		reg = <0x68>;
		status = "okay";

		ds3231_rtc: ds3231_rtc {
			compatible = "maxim,ds3231-rtc";
			status = "okay";
			isw-gpios = <&gpio0 10 (GPIO_ACTIVE_LOW | GPIO_PULL_UP)>;
		};
	};
};

/* shipsBellsV3 §8/§15.1 — the strike solenoid's gate, on GPIO18.
 *
 * WIRING (bench, 2026-07-31): GPIO18 -> R1 (10k) -> 2N3904 base, per
 * docs/design/assets/2026-07-28-shipsbells-12v-bench-driver.png. The schematic's
 * box is still labelled "MagTag ESP32-S2" — §16.1 moved this rig to the C6 and
 * the diagram has not caught up. Same 3.3 V logic either way.
 *
 * ACTIVE_HIGH, and the polarity is load-bearing rather than cosmetic. The
 * schematic's note 2: "GPIO low, or MCU unplugged -> R2 holds the gate at +12 V
 * -> MOSFET OFF. The coil cannot energise." So the driver is fail-safe OFF, and
 * declaring it ACTIVE_HIGH is what makes wire_gpio_outputs()'s
 * GPIO_OUTPUT_INACTIVE (../src/main.c) drive the pin physically LOW at boot —
 * i.e. de-energised. Inverting this flag would energise the coil for the entire
 * life of the image, which is the burnt-coil failure §8 spends three independent
 * layers defending against. Do not "tidy" it.
 *
 * GPIO18 chosen over the other free pins on this part: not strapping (4/5/8/9/15,
 * with 9 = BOOT button and 8 = the onboard RGB LED), not USB (12/13), not the
 * UART0 console (16/17), not SPI flash (24-29), not the DS3231's I2C pair (6/7)
 * or its SQW (10) — and deliberately NOT one of GPIO0-6, which are ADC1 and are
 * wanted for §11.1's coil-current measurement. It is also NOT an LP GPIO (0-7):
 * those are the only deep-sleep-wake-capable pins, and §16.1 states this rig is
 * mains-powered precisely because of the striker, so there is nothing to spend
 * one on.
 *
 * Modelled as gpio-leds only to get a handle with no new binding — nothing
 * lights — exactly as the MagTag's NeoPixel power gate is
 * (boards/esp32s2_saola_esp32s2.overlay:96).
 */
/ {
	strike {
		compatible = "gpio-leds";

		solenoid: solenoid {
			gpios = <&gpio0 18 GPIO_ACTIVE_HIGH>;
			label = "shipsBellsV3 strike solenoid (12 V bench driver)";
		};
	};

	aliases {
		/* The seam names the RTC through this alias, never through a node
		 * label, so a board that wires a different part (the design's
		 * RV-3028-C7 fallback, §99) re-points one line here and
		 * wallclock_target_read() is untouched. */
		wallclock = &ds3231_rtc;

		/* tuvm#82 — the OUTBOUND gpio seam. The ALIAS NAME NEVER REACHES nsl: a
		 * node names the silkscreen number (18), which ../src/main.c matches
		 * against this spec's own .pin. Declaring it here is what gets the pin
		 * driven de-energised at boot by wire_gpio_outputs(), independently of
		 * whether anything ever strikes. */
		gpioout = &solenoid;
	};
};
```

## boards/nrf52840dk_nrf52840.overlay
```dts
/*
 * tuvm/zephyr — Task 8 (nRF52840-DK acceptance bar). Expose the DK's on-board
 * BUTTON1 (button0 = P0.11, GPIO_PULL_UP | GPIO_ACTIVE_LOW, already defined in
 * the board DTS) as the physical edge source for the pulse seam. The Zephyr
 * GPIO callback in ../src/main.c binds to DT_ALIAS(pulsegpio) and, on each
 * press, calls gpio_target_fire(13) — the SAME logical pin the baked node
 * (PulseNodeDK.ns) registered via `gpio pin: 13 ...`. This overlay is applied
 * automatically for the nrf52840dk/nrf52840 board target; it is absent for the
 * native_sim gate (Task 7), so the alias — and the ISR guarded on it — compile
 * out there, leaving the Task-7 build byte-for-byte unchanged.
 *
 * NOTE (board reality, 2026-07-08): the plan's draft targeted the nrf52840
 * *dongle* (button on P1.06); the hardware on the bench is the *DK*, whose
 * BUTTON1 is P0.11. This overlay reflects the DK.
 */
/ {
	aliases {
		pulsegpio = &button0;
	};
};
```

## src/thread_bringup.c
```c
/* OpenThread bring-up for the Zephyr socket layer. ONE shared impl for every
   OpenThread target (nRF via NCS, ESP32-C6 via upstream 4.2): both toolchains
   expose the SAME no-arg OpenThread API. As of Zephyr 4.2 the OT integration was
   refactored out of subsys/net/l2/openthread/ into a standalone module
   (modules/openthread/, doc/releases/migration-guide-4.2.rst); its <openthread.h>
   — globally on the include path via that module's zephyr_include_directories —
   declares the non-deprecated no-arg calls (openthread_init/openthread_run/
   openthread_mutex_lock/openthread_mutex_unlock/openthread_get_default_instance).
   Only the net_if is fetched via the older <zephyr/net/openthread.h>
   openthread_get_default_context()->iface (that field, unlike ->instance, is not
   deprecated). This was two near-identical board files until 2026-07-20 (#59); the
   board-split's premise — "the C6 can't compile the nRF bring-up" — was false (an
   incomplete header probe), so they were collapsed. Re-split behind the
   thread_bringup.h seam only if NCS and upstream OT APIs actually diverge.

   ESP32-C6 CAVEAT (#59, 2026-07-20): this code is correct on stock Zephyr 4.2.0 but
   the C6 will still never attach on it — 4.2.0's drivers/ieee802154/ieee802154_esp32.c
   maps the radio stop() onto esp_ieee802154_disable() (a full teardown) where
   OpenThread only expects sleep. Upstream fixed it in 4.3.x (d66a39f7b5b "ieee802154:
   esp32: Fix start/stop API", plus a9eb90a20e9 for the 802.15.4 MAC universe). Our
   ~/zephyr-esp32 workspace carries those as branch tuvm-c6-radio-fix; on a plain
   v4.2.0 checkout the symptom is role stuck DETACHED with a provably correct dataset.

   Shape: enable -> admin-up the net_if -> poll role -> print, BLOCKING until the
   MTD attaches so the VM starts on a joined mesh. */
#include <zephyr/kernel.h>
#include <zephyr/net/net_if.h>
#include <zephyr/net/openthread.h>
#include <openthread.h>
#include <openthread/thread.h>
#include "thread_bringup.h"

void tuvm_thread_bringup(void) {
    (void)openthread_init();                        /* idempotent: L2 inited at boot */
    int rr = openthread_run();                       /* enable IPv6 + Thread -> attach */

    struct openthread_context *ctx = openthread_get_default_context();
    struct net_if *iface = ctx ? ctx->iface : net_if_get_default();
    /* openthread_run() enables IPv6+Thread so the node ATTACHES (ot-ctl ping /
       child table work), but it does NOT admin-up the Zephyr socket net_if — so
       zsock_sendto returns ENETDOWN (errno 115) even while attached.
       net_if_up() is THE fix. */
    int ur = iface ? net_if_up(iface) : -1;
    printk("thread: run=%d net_if_up=%d, joining...\n", rr, ur);

    otInstance *inst = openthread_get_default_instance();
    for (int i = 0; i < 300 && inst; i++) {          /* wait up to ~30s for attach */
        openthread_mutex_lock();
        otDeviceRole role = otThreadGetDeviceRole(inst);
        openthread_mutex_unlock();
        if (role == OT_DEVICE_ROLE_CHILD || role == OT_DEVICE_ROLE_ROUTER) {
            printk("thread: attached role=%d\n", role);
            return;
        }
        k_msleep(100);
    }
    printk("thread: attach timed out, continuing\n");
}
```

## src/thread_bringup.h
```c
#ifndef TUVM_THREAD_BRINGUP_H
#define TUVM_THREAD_BRINGUP_H

/* Bring the OpenThread mesh up for the Zephyr socket layer and BLOCK until the
   MTD attaches (role CHILD/ROUTER) or a ~30 s timeout elapses. Board-selected:
   NCS impl (backend/ncs) for nRF, upstream-4.2 impl (backend/zephyr) for the C6.
   Only compiled/linked when CONFIG_NET_L2_OPENTHREAD=y. */
void tuvm_thread_bringup(void);

#endif /* TUVM_THREAD_BRINGUP_H */
```
